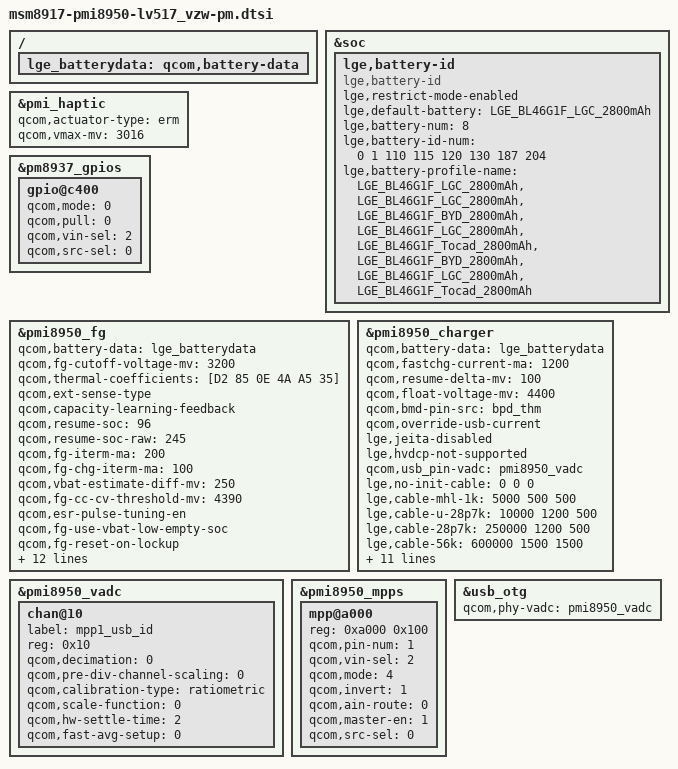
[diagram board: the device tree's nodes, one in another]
/*
 * Copyright (c) 2016, The Linux Foundation. All rights reserved.
 *
 * This program is free software; you can redistribute it and/or modify
 * it under the terms of the GNU General Public License version 2 and
 * only version 2 as published by the Free Software Foundation.
 *
 * This program is distributed in the hope that it will be useful,
 * but WITHOUT ANY WARRANTY; without even the implied warranty of
 * MERCHANTABILITY or FITNESS FOR A PARTICULAR PURPOSE.  See the
 * GNU General Public License for more details.
 */

/{
    lge_batterydata: qcom,battery-data {
         #include "../battery_profile/LGE_BL46G1F_LGC_2800mAh.dtsi"
         #include "../battery_profile/LGE_BL46G1F_Tocad_2800mAh.dtsi"
         #include "../battery_profile/LGE_BL46G1F_BYD_2800mAh.dtsi"
    };
};

&soc {
	lge,battery-id{
		compatible = "lge,battery-id";
		lge,restrict-mode-enabled;
		/*default battery profile*/
		lge,default-battery = "LGE_BL46G1F_LGC_2800mAh";
		/*Total number of combined of battery cell and battery id */
		lge,battery-num = <8>;
		/* battery id and battery profile match numbers */
		lge,battery-id-num = <0 1 110 115 120 130 187 204>;
		/* battery profile */
		lge,battery-profile-name = "LGE_BL46G1F_LGC_2800mAh",
						"LGE_BL46G1F_LGC_2800mAh",
						"LGE_BL46G1F_BYD_2800mAh",
						"LGE_BL46G1F_LGC_2800mAh",
						"LGE_BL46G1F_Tocad_2800mAh",
						"LGE_BL46G1F_BYD_2800mAh",
						"LGE_BL46G1F_LGC_2800mAh",
						"LGE_BL46G1F_Tocad_2800mAh";
	};
};

&pmi_haptic{
	status = "okay";
	qcom,actuator-type = "erm";
	qcom,vmax-mv = <3016>;
};

&pm8937_gpios {
	gpio@c400 {
		qcom,mode = <0>;
		qcom,pull = <0>;
		qcom,vin-sel = <2>;
		qcom,src-sel = <0>;
		status = "okay";
	};
};


&pmi8950_fg {
	qcom,battery-data = <&lge_batterydata>;
	qcom,fg-cutoff-voltage-mv = <3200>;
	qcom,thermal-coefficients = [D2 85 0E 4A A5 35];
	qcom,ext-sense-type;
	qcom,capacity-learning-feedback;
	qcom,resume-soc = <96>;
	qcom,resume-soc-raw = <245>;
	qcom,fg-iterm-ma = <200>;
	qcom,fg-chg-iterm-ma = <100>;
	qcom,vbat-estimate-diff-mv = <250>;
	qcom,fg-cc-cv-threshold-mv = <4390>;
	qcom,esr-pulse-tuning-en;
	qcom,fg-use-vbat-low-empty-soc;
	qcom,fg-reset-on-lockup;
	qcom,fg-cc-soc-limit-pct = <120>;
	qcom,fg-control-slope-limiter;
	qcom,fg-slope-limit-high-temp-chg = <6>;
	qcom,fg-slope-limit-high-temp-dischg = <6>;
	qcom,fg-slope-limit-low-temp-chg = <14>;
	qcom,fg-slope-limit-low-temp-dischg =<14>;
	qcom,fg-dischg-voltage-gain-ctrl;
	qcom,fg-dischg-voltage-gain-soc = <7 15 20>;
	qcom,fg-dischg-med-voltage-gain = <5 4 4>;
	qcom,fg-dischg-high-voltage-gain = <5 5 4>;
	qcom,cl-max-limit-deciperc= <50>;
	qcom,cl-min-limit-deciperc= <200>;
};

&pmi8950_charger {
	qcom,battery-data = <&lge_batterydata>;
	qcom,fastchg-current-ma = <1200>;
	qcom,resume-delta-mv = <100>;
	qcom,float-voltage-mv = <4400>;
	qcom,bmd-pin-src = "bpd_thm";
	qcom,override-usb-current;
	lge,jeita-disabled;
	lge,hvdcp-not-supported;

	qcom,usb_pin-vadc = <&pmi8950_vadc>;

	/* ref resistance 200K */
	lge,no-init-cable = <0 0 0>;
	lge,cable-mhl-1k = <5000 500 500>;
	lge,cable-u-28p7k = <10000 1200 500>;
	lge,cable-28p7k = <250000 1200 500>;
	lge,cable-56k = <600000 1500 1500>;
	lge,cable-100k = <620000 1200 500>;
	lge,cable-130k = <780000 1500 1500>;
	lge,cable-180k = <870000 1200 500>;
	lge,cable-200k = <910000 1200 500>;
	lge,cable-220k = <960000 1200 500>;
	lge,cable-270k = <1050000 1200 500>;
	lge,cable-330k = <1150000 1200 500>;
	lge,cable-620k = <1380000 1200 500>;
	lge,cable-910k = <1630000 1500 1500>;
	lge,cable-none = <1900000 1200  500>;

	lge,usb-max-current-ma = <1200>;
};

&pmi8950_vadc {
	chan@10 {
		label = "mpp1_usb_id";
		reg = <0x10>;
		qcom,decimation = <0>;
		qcom,pre-div-channel-scaling = <0>;
		qcom,calibration-type = "ratiometric";
		qcom,scale-function = <0>;
		qcom,hw-settle-time = <2>;
		qcom,fast-avg-setup = <0>;
	};
};

&pmi8950_mpps {
	mpp@a000 {
		reg = <0xa000 0x100>;
		qcom,pin-num = <1>;
		status = "okay";
		qcom,vin-sel = <2>;
		qcom,mode = <4>; /* AIN input */
		qcom,invert = <1>; /* Enable MPP */
		qcom,ain-route = <0>; /* AMUX 5 */
		qcom,master-en = <1>;
		qcom,src-sel = <0>; /* Function constant */
	};
};

&usb_otg {
	qcom,phy-vadc = <&pmi8950_vadc>;
};
